# jbr_MDR1986VE3 register map
Registers are 32-bit, access not given, no defined reset value unless marked. A register's access mark holds for its fields unless they carry their own. Addresses are absolute; registers are grouped by the start of their names; [hi:lo] are bit positions; {n}, {i} and the like mark numbered series; 'fields as' and 'values as' point back to an identical list.

## ETH1
0x30000000 ETH1_Dilimiter 16-bit
0x30000002 ETH1_MAC_T 16-bit
0x30000004 ETH1_MAC_M 16-bit
0x30000006 ETH1_MAC_H 16-bit
{0x30000008+2i} ETH1_HASH{i} 16-bit (i=0..3)
0x30000010 ETH1_IPG 16-bit
0x30000012 ETH1_PSC 16-bit
0x30000014 ETH1_BAG 16-bit
0x30000016 ETH1_JitterWnd 16-bit
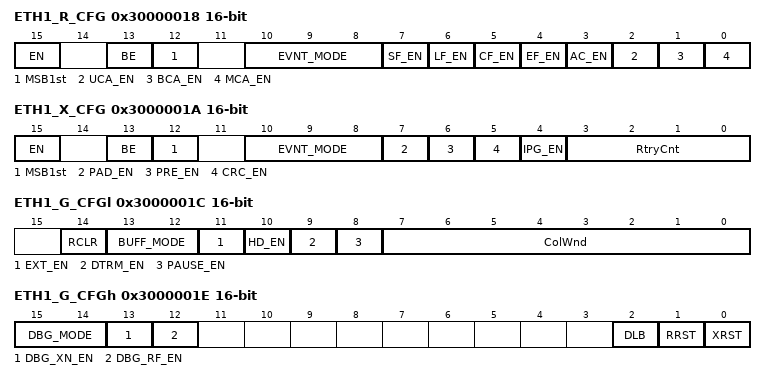
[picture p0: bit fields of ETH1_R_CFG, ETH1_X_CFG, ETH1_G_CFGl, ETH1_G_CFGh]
0x30000018 ETH1_R_CFG 16-bit
  [15] EN, [13] BE, [12] MSB1st, [10:8] EVNT_MODE, [7] SF_EN, [6] LF_EN, [5] CF_EN, [4] EF_EN, [3] AC_EN, [2] UCA_EN, [1] BCA_EN, [0] MCA_EN
0x3000001A ETH1_X_CFG 16-bit
  [15] EN, [13] BE, [12] MSB1st, [10:8] EVNT_MODE, [7] PAD_EN, [6] PRE_EN, [5] CRC_EN, [4] IPG_EN, [3:0] RtryCnt
0x3000001C ETH1_G_CFGl 16-bit
  [14] RCLR, [13:12] BUFF_MODE, [11] EXT_EN, [10] HD_EN, [9] DTRM_EN, [8] PAUSE_EN, [7:0] ColWnd
0x3000001E ETH1_G_CFGh 16-bit
  [15:14] DBG_MODE, [13] DBG_XN_EN, [12] DBG_RF_EN, [2] DLB, [1] RRST, [0] XRST
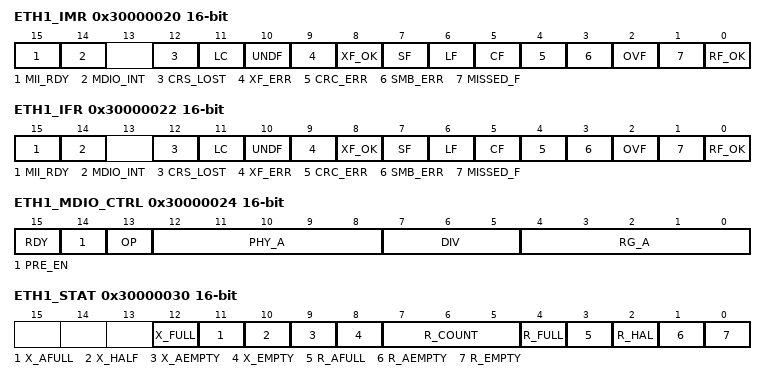
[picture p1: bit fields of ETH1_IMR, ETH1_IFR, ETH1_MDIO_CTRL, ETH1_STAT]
0x30000020 ETH1_IMR 16-bit
  [15] MII_RDY, [14] MDIO_INT, [12] CRS_LOST, [11] LC, [10] UNDF, [9] XF_ERR, [8] XF_OK, [7] SF, [6] LF, [5] CF, [4] CRC_ERR, [3] SMB_ERR, [2] OVF, [1] MISSED_F, [0] RF_OK
0x30000022 ETH1_IFR 16-bit
  fields as ETH1_IMR
0x30000024 ETH1_MDIO_CTRL 16-bit
  [15] RDY, [14] PRE_EN, [13] OP, [12:8] PHY_A, [7:5] DIV, [4:0] RG_A
0x30000026 ETH1_MDIO_DATA 16-bit
0x30000028 ETH1_R_Head 16-bit
0x3000002A ETH1_X_Tail 16-bit
0x3000002C ETH1_R_Tail 16-bit
0x3000002E ETH1_X_Head 16-bit
0x30000030 ETH1_STAT 16-bit
  [12] X_FULL, [11] X_AFULL, [10] X_HALF, [9] X_AEMPTY, [8] X_EMPTY, [7:5] R_COUNT, [4] R_FULL, [3] R_AFULL, [2] R_HAL, [1] R_AEMPTY, [0] R_EMPTY

## PHY1
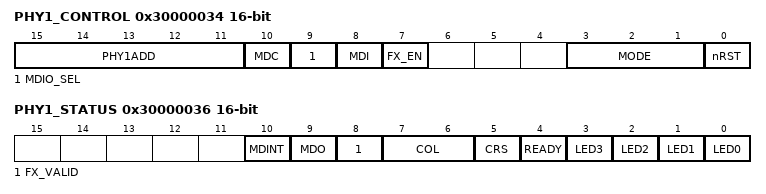
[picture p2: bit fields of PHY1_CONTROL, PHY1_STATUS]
0x30000034 PHY1_CONTROL 16-bit
  [15:11] PHY1ADD, [10] MDC, [9] MDIO_SEL, [8] MDI, [7] FX_EN, [3:1] MODE, [0] nRST
0x30000036 PHY1_STATUS 16-bit
  [10] MDINT, [9] MDO, [8] FX_VALID, [7:6] COL, [5] CRS, [4] READY, [n] LED{n} (n=0..3)

## ETH2
0x34000000 ETH2_Dilimiter 16-bit
0x34000002 ETH2_MAC_T 16-bit
0x34000004 ETH2_MAC_M 16-bit
0x34000006 ETH2_MAC_H 16-bit
{0x34000008+2i} ETH2_HASH{i} 16-bit (i=0..3)
0x34000010 ETH2_IPG 16-bit
0x34000012 ETH2_PSC 16-bit
0x34000014 ETH2_BAG 16-bit
0x34000016 ETH2_JitterWnd 16-bit
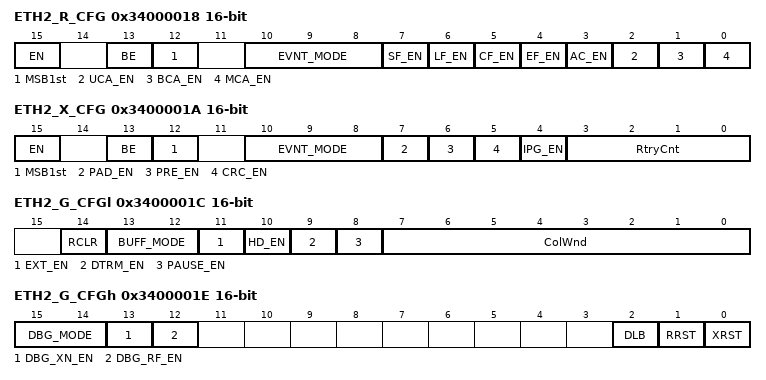
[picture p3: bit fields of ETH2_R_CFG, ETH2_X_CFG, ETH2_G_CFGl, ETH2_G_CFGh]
0x34000018 ETH2_R_CFG 16-bit
  [15] EN, [13] BE, [12] MSB1st, [10:8] EVNT_MODE, [7] SF_EN, [6] LF_EN, [5] CF_EN, [4] EF_EN, [3] AC_EN, [2] UCA_EN, [1] BCA_EN, [0] MCA_EN
0x3400001A ETH2_X_CFG 16-bit
  [15] EN, [13] BE, [12] MSB1st, [10:8] EVNT_MODE, [7] PAD_EN, [6] PRE_EN, [5] CRC_EN, [4] IPG_EN, [3:0] RtryCnt
0x3400001C ETH2_G_CFGl 16-bit
  [14] RCLR, [13:12] BUFF_MODE, [11] EXT_EN, [10] HD_EN, [9] DTRM_EN, [8] PAUSE_EN, [7:0] ColWnd
0x3400001E ETH2_G_CFGh 16-bit
  [15:14] DBG_MODE, [13] DBG_XN_EN, [12] DBG_RF_EN, [2] DLB, [1] RRST, [0] XRST
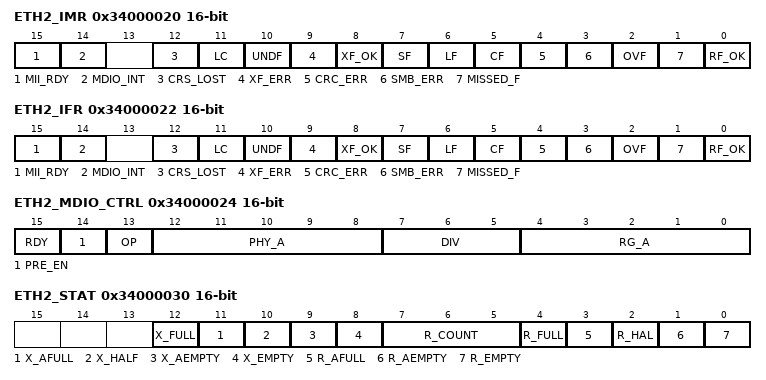
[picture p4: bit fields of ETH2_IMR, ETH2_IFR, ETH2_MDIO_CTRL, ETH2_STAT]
0x34000020 ETH2_IMR 16-bit
  [15] MII_RDY, [14] MDIO_INT, [12] CRS_LOST, [11] LC, [10] UNDF, [9] XF_ERR, [8] XF_OK, [7] SF, [6] LF, [5] CF, [4] CRC_ERR, [3] SMB_ERR, [2] OVF, [1] MISSED_F, [0] RF_OK
0x34000022 ETH2_IFR 16-bit
  fields as ETH2_IMR
0x34000024 ETH2_MDIO_CTRL 16-bit
  [15] RDY, [14] PRE_EN, [13] OP, [12:8] PHY_A, [7:5] DIV, [4:0] RG_A
0x34000026 ETH2_MDIO_DATA 16-bit
0x34000028 ETH2_R_Head 16-bit
0x3400002A ETH2_X_Tail 16-bit
0x3400002C ETH2_R_Tail 16-bit
0x3400002E ETH2_X_Head 16-bit
0x34000030 ETH2_STAT 16-bit
  [12] X_FULL, [11] X_AFULL, [10] X_HALF, [9] X_AEMPTY, [8] X_EMPTY, [7:5] R_COUNT, [4] R_FULL, [3] R_AFULL, [2] R_HAL, [1] R_AEMPTY, [0] R_EMPTY

## PHY
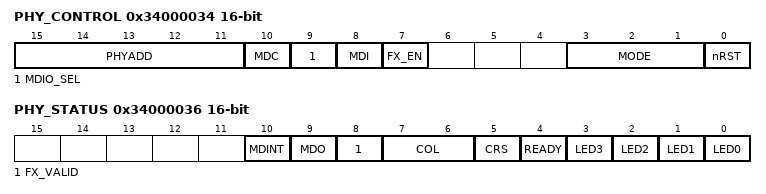
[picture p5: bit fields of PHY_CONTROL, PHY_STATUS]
0x34000034 PHY_CONTROL 16-bit
  [15:11] PHYADD, [10] MDC, [9] MDIO_SEL, [8] MDI, [7] FX_EN, [3:1] MODE, [0] nRST
0x34000036 PHY_STATUS 16-bit
  [10] MDINT, [9] MDO, [8] FX_VALID, [7:6] COL, [5] CRS, [4] READY, [n] LED{n} (n=0..3)

## KEYPAD
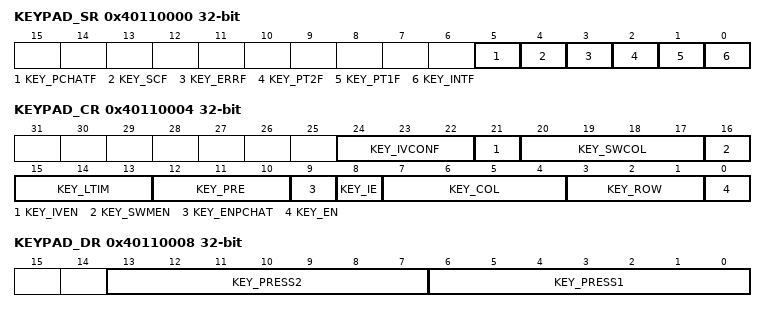
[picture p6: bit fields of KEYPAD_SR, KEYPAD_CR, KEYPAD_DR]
0x40110000 KEYPAD_SR
  [5] KEY_PCHATF, [4] KEY_SCF, [3] KEY_ERRF, [2] KEY_PT2F, [1] KEY_PT1F, [0] KEY_INTF
0x40110004 KEYPAD_CR
  [24:22] KEY_IVCONF, [21] KEY_IVEN, [20:17] KEY_SWCOL, [16] KEY_SWMEN, [15:13] KEY_LTIM, [12:10] KEY_PRE, [9] KEY_ENPCHAT, [8] KEY_IE, [7:4] KEY_COL, [3:1] KEY_ROW, [0] KEY_EN
0x40110008 KEYPAD_DR
  [13:7] KEY_PRESS2, [6:0] KEY_PRESS1
